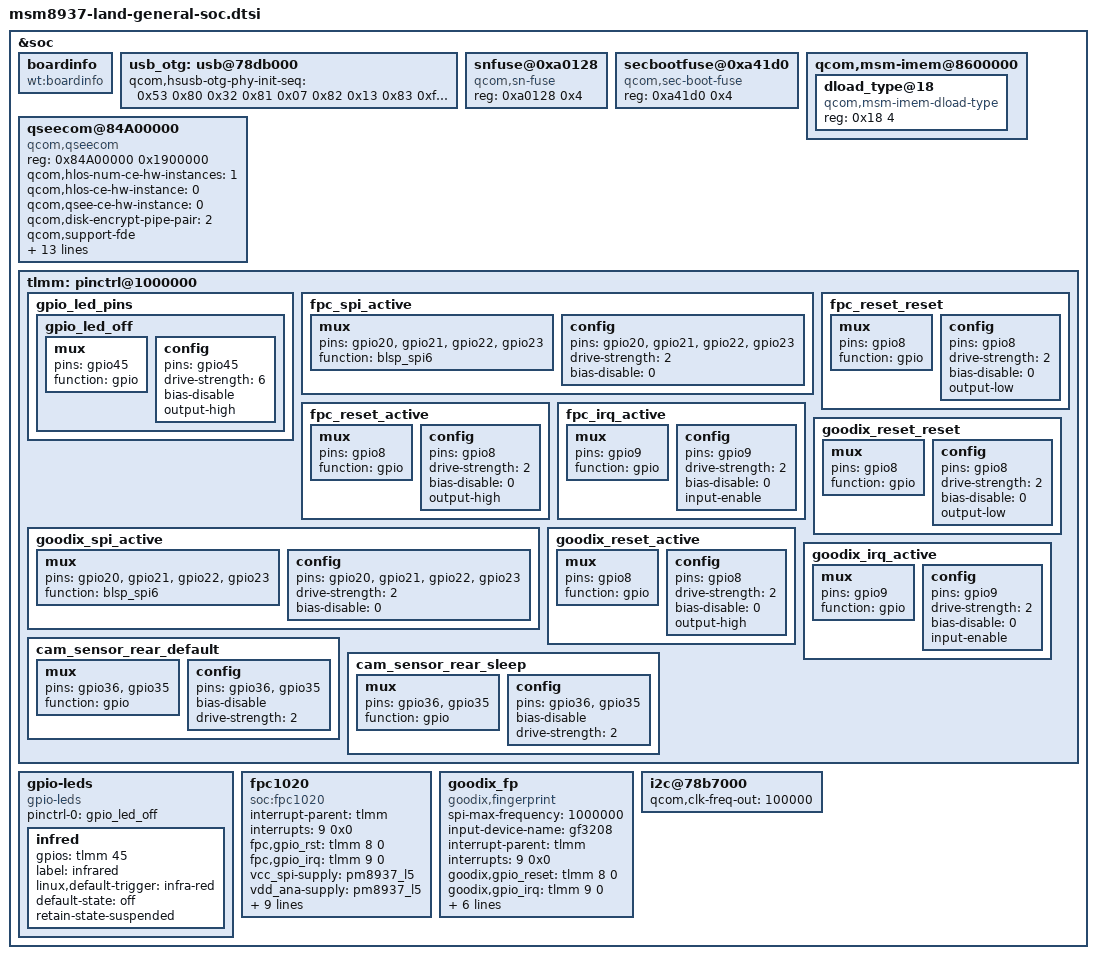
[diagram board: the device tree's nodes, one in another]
 
&soc {
	boardinfo {
		compatible = "wt:boardinfo";
	};

	usb_otg: usb@78db000 {
		qcom,hsusb-otg-phy-init-seq =
			 <0x53 0x80 0x32 0x81 0x07 0x82 0x13 0x83 0xffffffff>;
	};

	snfuse@0xa0128 {
		compatible = "qcom,sn-fuse";
		reg = <0xa0128 0x4>;
		reg-names = "sn-base";
	};

	secbootfuse@0xa41d0 {
		compatible = "qcom,sec-boot-fuse";
		reg = <0xa41d0 0x4>;
		reg-names = "sec-boot-base";
	};

	qcom,msm-imem@8600000 {
		/delete-node/ dload_type@1c;
		dload_type@18 {
			compatible = "qcom,msm-imem-dload-type";
			reg = <0x18 4>;
		};
	};

	qseecom@84A00000 {
		compatible = "qcom,qseecom";
		reg = <0x84A00000 0x1900000>;
		reg-names = "secapp-region";
		qcom,hlos-num-ce-hw-instances = <1>;
		qcom,hlos-ce-hw-instance = <0>;
		qcom,qsee-ce-hw-instance = <0>;
		qcom,disk-encrypt-pipe-pair = <2>;
		qcom,support-fde;
		qcom,appsbl-qseecom-support;
		qcom,msm-bus,name = "qseecom-noc";
		qcom,msm-bus,num-cases = <4>;
		qcom,msm-bus,num-paths = <1>;
		qcom,support-bus-scaling;
		qcom,msm-bus,vectors-KBps =
			<55 512 0 0>,
			<55 512 0 0>,
			<55 512 120000 1200000>,
			<55 512 393600 3936000>;
		clocks = <&gcc clk_crypto_clk_src>,
			 <&gcc clk_gcc_crypto_clk>,
			 <&gcc clk_gcc_crypto_ahb_clk>,
			 <&gcc clk_gcc_crypto_axi_clk>;
		clock-names = "core_clk_src", "core_clk",
				"iface_clk", "bus_clk";
		qcom,ce-opp-freq = <100000000>;
	};
        /delete-node/ qseecom@85b00000;
		
	tlmm: pinctrl@1000000 {
		gpio_led_pins {
			gpio_led_off: gpio_led_off {
				mux {
					pins = "gpio45";
					function = "gpio";
				};
				config {
					pins = "gpio45";
					drive-strength = <6>;
					bias-disable;
					output-high;
				};
			};
		};

		fpc_spi_active: fpc_spi_active{
			mux {
				pins = "gpio20", "gpio21", "gpio22", "gpio23";
				function = "blsp_spi6";
			};
			config {
				pins = "gpio20", "gpio21", "gpio22", "gpio23";
				drive-strength = <2>;
				bias-disable = <0>;
			};
		};

		fpc_reset_reset: fpc_reset_reset{
			mux {
				pins = "gpio8";
				function = "gpio";
			};
			config {
				pins = "gpio8";
				drive-strength = <2>;
				bias-disable = <0>;
				output-low;
			};
		};

		fpc_reset_active: fpc_reset_active{
			mux {
				pins = "gpio8";
				function = "gpio";
			};
			config {
				pins = "gpio8";
				drive-strength = <2>;
				bias-disable = <0>;
				output-high;
			};
		};

		fpc_irq_active: fpc_irq_active {
			mux {
				pins = "gpio9";
				function = "gpio";
			};
			config {
				pins = "gpio9";
				drive-strength = <2>;
				bias-disable = <0>;
				input-enable;
			};
		};

		goodix_spi_active: goodix_spi_active{
			mux {
				pins = "gpio20", "gpio21", "gpio22", "gpio23";
				function = "blsp_spi6";
			};
			config {
				pins = "gpio20", "gpio21", "gpio22", "gpio23";
				drive-strength = <2>;
				bias-disable = <0>;
			};
		};

		goodix_reset_reset: goodix_reset_reset{
			mux {
				pins = "gpio8";
				function = "gpio";
			};
			config {
				pins = "gpio8";
				drive-strength = <2>;
				bias-disable = <0>;
				output-low;
			};
		};

		goodix_reset_active: goodix_reset_active{
			mux {
				pins = "gpio8";
				function = "gpio";
			};
			config {
				pins = "gpio8";
				drive-strength = <2>;
				bias-disable = <0>;
				output-high;
			};
		};

		goodix_irq_active: goodix_irq_active {
			mux {
				pins = "gpio9";
				function = "gpio";
			};
			config {
				pins = "gpio9";
				drive-strength = <2>;
				bias-disable = <0>;
				input-enable;
			};
		};

		/delete-node/ cam_sensor_rear_reset;
		/delete-node/ cam_sensor_rear_reset_sleep;
		/delete-node/ cam_sensor_rear_standby;
		/delete-node/ cam_sensor_rear_standby_sleep;

		cam_sensor_rear_default: cam_sensor_rear_default {
			mux {
				pins = "gpio36", "gpio35";
				function = "gpio";
			};
			config {
				pins = "gpio36","gpio35";
				bias-disable;
				drive-strength = <2>;
			};
		};

		cam_sensor_rear_sleep: cam_sensor_rear_sleep {
			mux {
				pins = "gpio36","gpio35";
				function = "gpio";
			};
			config {
				pins = "gpio36","gpio35";
				bias-disable;
				drive-strength = <2>;
			};
		};

		/delete-node/ cam_sensor_rear_vana;
		/delete-node/ cam_sensor_rear_vana_sleep;
	};

	gpio-leds {
		compatible = "gpio-leds";
		status = "okay";
		pinctrl-names = "default";
		pinctrl-0 = <&gpio_led_off>;

		infred {
			gpios = <&tlmm 45 0>;
			label = "infrared";
			linux,default-trigger = "infra-red";
			default-state = "off";
			retain-state-suspended;
		};

	};

	fpc1020 {
		compatible = "soc:fpc1020";

		interrupt-parent = <&tlmm>;
		interrupts = <9 0x0>;

		fpc,gpio_rst    = <&tlmm 8 0>;
		fpc,gpio_irq    = <&tlmm 9 0>;

		vcc_spi-supply  = <&pm8937_l5>;
		vdd_ana-supply  = <&pm8937_l5>;
		vdd_io-supply   = <&pm8937_l5>;

		fpc,enable-on-boot;
		/delete-property/
		fpc,enable-wakeup;

		fpc,spi-max-frequency = <4800000>;

		/* Only for SPI Clock Handled by Linux */
		clock-names = "iface_clk", "core_clk";
		clocks = <&gcc clk_gcc_blsp1_ahb_clk>,
				<&gcc clk_gcc_blsp1_qup1_spi_apps_clk>;

		pinctrl-names = "fpc1020_spi_active",
			"fpc1020_reset_reset",
			"fpc1020_reset_active",
			"fpc1020_irq_active";

		pinctrl-0 = <&fpc_spi_active>;
		pinctrl-1 = <&fpc_reset_reset>;
		pinctrl-2 = <&fpc_reset_active>;
		pinctrl-3 = <&fpc_irq_active>;
	};

	goodix_fp {
		compatible = "goodix,fingerprint";
		spi-max-frequency = <1000000>;
		input-device-name = "gf3208";
		interrupt-parent = <&tlmm>;
		interrupts = <9 0x0>;

		goodix,gpio_reset    = <&tlmm 8 0>;
		goodix,gpio_irq      = <&tlmm 9 0>;

		clock-names = "iface_clk", "core_clk";
		clocks = <&gcc clk_gcc_blsp1_ahb_clk>,
				<&gcc clk_gcc_blsp1_qup1_spi_apps_clk>;

		pinctrl-names = "goodixfp_spi_active",
			"goodixfp_reset_reset",
			"goodixfp_reset_active",
			"goodixfp_irq_active";

		pinctrl-0 = <&goodix_spi_active>;
		pinctrl-1 = <&goodix_reset_reset>;
		pinctrl-2 = <&goodix_reset_active>;
		pinctrl-3 = <&goodix_irq_active>;
	};

	i2c@78b7000 {
		qcom,clk-freq-out = <100000>;
		status = "okay";
	};
};
